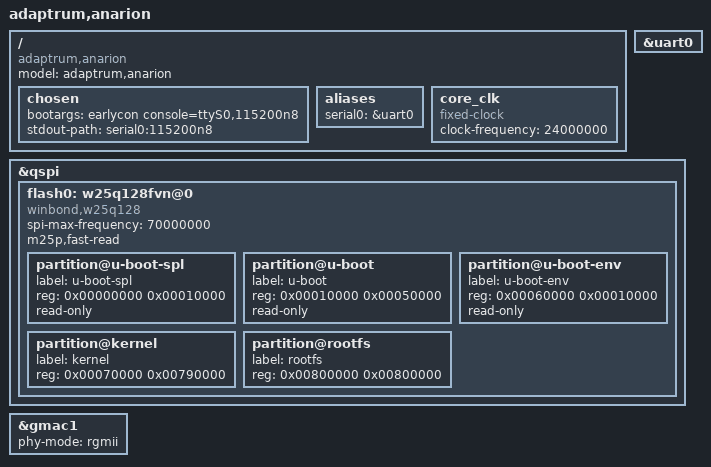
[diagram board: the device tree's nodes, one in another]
/*
 * (C) Copyright 2017 Adaptrum, Inc.
 * Written by Alexandru Gagniuc <alex.g@adaptrum.com> for Adaptrum, Inc.
 * Licensed under the GPLv2 or (at your option) any later version
 */

/dts-v1/;

#include "adaptrum_anarion.dtsi"

/ {
	model = "adaptrum,anarion";
	compatible = "adaptrum,anarion";

	chosen {
		bootargs = "earlycon console=ttyS0,115200n8";
		stdout-path = "serial0:115200n8";
	};

	aliases {
		serial0 = &uart0;
	};

	core_clk: core_clk {
		#clock-cells = <0>;
		compatible = "fixed-clock";
		clock-frequency = <24000000>;
	};
};

&uart0 {
	status = "okay";
};

&qspi {
	status = "okay";
	flash0: w25q128fvn@0 {
		#address-cells = <1>;
		#size-cells = <1>;
		compatible = "winbond,w25q128", "jedec,spi-nor";
		spi-max-frequency = <70000000>;
		m25p,fast-read;

		partition@u-boot-spl {
			label = "u-boot-spl";
			reg = <0x00000000 0x00010000>;
			read-only;
		};
		partition@u-boot {
			label = "u-boot";
			reg = <0x00010000 0x00050000>;
			read-only;
		};
		partition@u-boot-env {
			label = "u-boot-env";
			reg = <0x00060000 0x00010000>;
			read-only;
		};
		partition@kernel {
			label = "kernel";
			reg = <0x00070000 0x00790000>;
		};
		partition@rootfs {
			label = "rootfs";
			reg = <0x00800000 0x00800000>;
		};
	};
};

&gmac1 {
	phy-mode = "rgmii";
	status = "okay";
};
